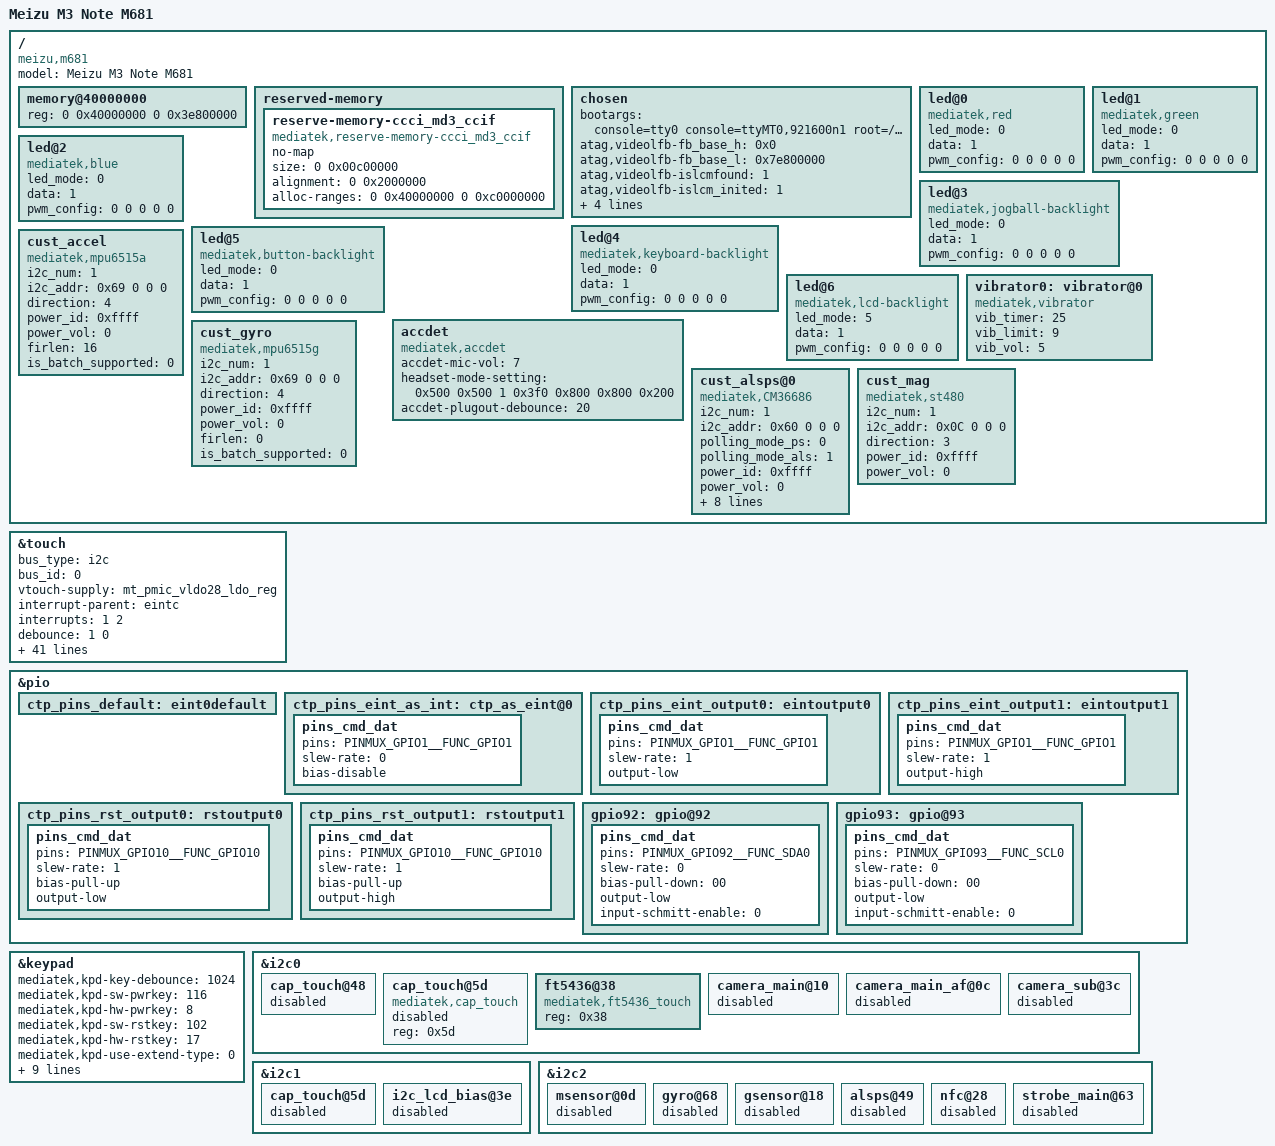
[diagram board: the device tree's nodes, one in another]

/*
 * !!! DEAD FILE — DO NOT EDIT FOR DEVICE CHANGES !!!  (m681 v240)
 * The boot.img packs ONLY wt6755_66_sz_l.dtb:
 *   m681_defconfig: CONFIG_BUILD_ARM64_APPENDED_DTB_IMAGE_NAMES="wt6755_66_sz_l"
 * Nothing in this file reaches the flashed kernel. All v239h11/h12 overrides
 * that were written here (keypad, led_mode, gpio92/93) were silently discarded
 * and had to be re-applied in wt6755_66_sz_l.dts. Put ALL board/DTS changes in
 * arch/arm64/boot/dts/wt6755_66_sz_l.dts instead. Kept only for git history.
 */
/dts-v1/;

#include "mt6755.dtsi"
#include "cust.dtsi"

/ {
	model = "Meizu M3 Note M681";
	compatible = "meizu,m681", "mediatek,mt6755";

	memory@40000000 {
		device_type = "memory";
		reg = <0 0x40000000 0 0x3e800000>;
	};

	reserved-memory {
		#address-cells = <2>;
		#size-cells = <2>;
		ranges;

		reserve-memory-ccci_md3_ccif {
			compatible = "mediatek,reserve-memory-ccci_md3_ccif";
			no-map;
			size = <0 0x00c00000>;
			alignment = <0 0x2000000>;
			alloc-ranges = <0 0x40000000 0 0xc0000000>;
		};
	};

	/* chosen */
	chosen {
		bootargs = "console=tty0 console=ttyMT0,921600n1 root=/dev/ram initrd=0x44000000,0x4b434e loglevel=4 printk.disable_uart=1 maxcpus=1 clk_ignore_unused";

		/* Real M681 boots through LK, so keep the fallback in sync with LK handoff. */
		/* fb buffer is reserved using this dts by memory node above */
		atag,videolfb-fb_base_h = <0x0>;
		atag,videolfb-fb_base_l = <0x7e800000>;
		atag,videolfb-islcmfound = <1>;
		atag,videolfb-islcm_inited = <1>;
		atag,videolfb-fps= <5716>;
		atag,videolfb-vramSize= <0x01be0000>;
		atag,videolfb-lcmname= "ili9885_fhd_dsi_vdo_txd1";
	};
	led@0 {
		compatible = "mediatek,red";
		led_mode = <0>;
		data = <1>;
		pwm_config = <0 0 0 0 0>;
	};
	led@1 {
		compatible = "mediatek,green";
		led_mode = <0>;
		data = <1>;
		pwm_config = <0 0 0 0 0>;
	};
	led@2 {
		compatible = "mediatek,blue";
		led_mode = <0>;
		data = <1>;
		pwm_config = <0 0 0 0 0>;
	};
	led@3 {
		compatible = "mediatek,jogball-backlight";
		led_mode = <0>;
		data = <1>;
		pwm_config = <0 0 0 0 0>;
	};
	led@4 {
		compatible = "mediatek,keyboard-backlight";
		led_mode = <0>;
		data = <1>;
		pwm_config = <0 0 0 0 0>;
	};
	led@5 {
		compatible = "mediatek,button-backlight";
		led_mode = <0>;
		data = <1>;
		pwm_config = <0 0 0 0 0>;
	};
	led@6 {
		compatible = "mediatek,lcd-backlight";
		/* m681 v239h12: was <7> (out of range — enum only 0..5). Stock m6
		 * uses <5> = MT65XX_LED_MODE_CUST_BLS_PWM, the only mode that
		 * hooks the backlight into the display blank/unblank path via the
		 * BLS/DISP_PWM block. led_mode=7 fell through to MODE_NONE, so the
		 * LED subsystem never controlled the BL and it stayed on at the
		 * LCM-init level forever (incl. when screen locked). */
		led_mode = <5>;
		data = <1>;
		pwm_config = <0 0 0 0 0>;
	};
	vibrator0:vibrator@0 {
		compatible = "mediatek,vibrator";
		vib_timer = <25>;
		vib_limit = <9>;
		vib_vol= <5>;
	};
	accdet {
		compatible = "mediatek,accdet";
		accdet-mic-vol = <7>;
		headset-mode-setting = <0x500 0x500 1 0x3f0 0x800 0x800 0x200>;
		accdet-plugout-debounce = <20>;
	};
/*  start sensor */
	/* m681 (wt6755_66_sz_l stock) sensors. alsps=CM36686, accel+gyro=MPU6515,
	 * mag=ST480, all on i2c bus 1. Chip + i2c_addr + direction taken from the
	 * stock m3note cust_acc.c/cust_gyro.c/cust_mag.c. compatible strings match
	 * the 3.18 driver get_*_dts_func() name lookups. */
	cust_accel {
		compatible = "mediatek,mpu6515a";
		i2c_num = <1>;
		i2c_addr = <0x69 0 0 0>;
		direction = <4>;
		power_id = <0xffff>;
		power_vol = <0>;
		firlen = <16>;
		is_batch_supported = <0>;
	};
	cust_gyro {
		compatible = "mediatek,mpu6515g";
		i2c_num = <1>;
		i2c_addr = <0x69 0 0 0>;
		direction = <4>;
		power_id = <0xffff>;
		power_vol = <0>;
		firlen = <0>;
		is_batch_supported = <0>;
	};
	cust_alsps@0 {
		compatible 				= "mediatek,CM36686";
		i2c_num 				= <1>;
		i2c_addr 				= <0x60 0 0 0>;
		polling_mode_ps			= <0>;
		polling_mode_als		= <1>;
		power_id   				= <0xffff>;
		power_vol  				= <0>;
		/* Total has 15 level*/
		als_level  				= <0 257 637 1027 2297 5588 6730 11301 20449 25768 31122 45552 57937 57937 57937>;
		/*  Total has 16 range*/
		als_value  				= <0 132 304 502 1004 2003 3006 5006 8004 10000 12000 16000 20000 20000 20000 20000>;
		ps_threshold_high		=  <70>;
		ps_threshold_low		=  <40>;
		is_batch_supported_ps	= <1>;
		is_batch_supported_als	= <1>;
	};
	cust_mag {
		compatible = "mediatek,st480";
		i2c_num = <1>;
		i2c_addr = <0x0C 0 0 0>;
		direction = <3>;
		power_id = <0xffff>;
		power_vol = <0>;
	};
/* end sensor */
};

/* TOUCH: ported verbatim from meizu_m6.dts — touch worked on m6, same MT6755
 * family/routing (INT=GPIO1, RST=GPIO42, vtouch=VLDO28, i2c0). m681 panel chip
 * confirmed via on-device i2c0 scan; ft5x26@0x38 enabled as the m6-proven default. */
&touch {
	bus_type = "i2c";
	bus_id = <0>;
	/* M6: stock Flyme DTB powers the touch panel from vldo28 (vtouch-supply =
	 * ldo_vldo28), NOT the SoC-default "vtouch" rail. mt6755.dtsi inherits
	 * vtouch-supply=<&mt_pmic_vtouch_ldo_reg>, but this PMIC has no VTOUCH LDO
	 * -> regulator_get(vtouch) returns -EPROBE_DEFER forever -> VLDO28 never
	 * enabled -> GT9xx chip unpowered -> i2c no-ACK at 0x5d (only bias 0x3e
	 * answers on i2c-0). Re-point the supply at the real rail so the framework
	 * enables it. FACT: live LDO_VLDO28_STATUS=0 before, stock vtouch-supply=
	 * ldo_vldo28; FORGE I2C0 SCAN showed only 0x3e ACK. */
	vtouch-supply = <&mt_pmic_vldo28_ldo_reg>;
	/* M6: ft5x26 takes its touch IRQ via irq_of_parse_and_map(touch_node,0).
	 * Stock Flyme touch node has interrupt-parent=<&eintc> interrupts=<1 2>
	 * (EINT line 1 = GPIO1 INT, type 2 = falling edge). GT9xx never reached
	 * IRQ setup (died at i2c-test) so this was latent; ft5x26 needs it. */
	interrupt-parent = <&eintc>;
	interrupts = <1 2>;
	debounce = <1 0>;
	charger_supported = <1>;
	product = "Jim";
	slave_address = <93 72 0 0 0 0 0 0 0 0 0 0 0 0 0 0>;
	algo_id = <1>;
	hmx_irq_config = <3>;
	goodix_irq_config = <2>;
	need_wd_check_status = <1>;
	x_max = <720>;
	y_max = <1280>;
	x_max_mt = <720>;
	y_max_mt = <1280>;
	goodix,product_id = "GT917D";
	goodix,test-types = <0x80007>;/*test types*/
	goodix,panel-max = <3948>;
	goodix,panel-min = <1897>;
	goodix,panel-deviation = <400>;
	goodix,key-max = <0>;
	goodix,key-min = <0>;
	goodix,key-nc = <0>;/*key test not check*/
	goodix,special_raw_data_limit = <>;
	goodix,shortcircut-threshold = <0>;
	fw_upgrade_delay = <30000>;
	/* stock Flyme DTB value (chip outputs 1080x1920-space coords) */
	tpd-resolution = <1080 1920>;
	use-tpd-button = <0>;
	tpd-key-num = <3>;
	tpd-key-local= <139 172 158 0>;
	tpd-key-dim-local = <90 883 100 40 230 883 100 40 370 883 100 40 0 0 0 0>;
	tpd-max-touch-num = <5>;
	tpd-filter-enable = <1>;
	tpd-filter-pixel-density = <146>;
	tpd-filter-custom-prameters = <0 0 0 0 0 0 0 0 0 0 0 0>;
	tpd-filter-custom-speed = <0 0 0>;
	pinctrl-names = "default", "state_eint_as_int", "state_eint_output0", "state_eint_output1",
		"state_rst_output0", "state_rst_output1";
	pinctrl-0 = <&ctp_pins_default>;
	pinctrl-1 = <&ctp_pins_eint_as_int>;
	pinctrl-2 = <&ctp_pins_eint_output0>;
	pinctrl-3 = <&ctp_pins_eint_output1>;
	pinctrl-4 = <&ctp_pins_rst_output0>;
	pinctrl-5 = <&ctp_pins_rst_output1>;
	status = "okay";
};
&pio {
	ctp_pins_default: eint0default {
	};
	ctp_pins_eint_as_int: ctp_as_eint@0 {
		pins_cmd_dat {
			pins = <PINMUX_GPIO1__FUNC_GPIO1>;
			slew-rate = <0>;
			bias-disable;
		};
	};
	ctp_pins_eint_output0: eintoutput0 {
		pins_cmd_dat {
			pins = <PINMUX_GPIO1__FUNC_GPIO1>;
			slew-rate = <1>;
			output-low;
		};
	};
	ctp_pins_eint_output1: eintoutput1 {
		pins_cmd_dat {
			pins = <PINMUX_GPIO1__FUNC_GPIO1>;
			slew-rate = <1>;
			output-high;
		};
	};
	ctp_pins_rst_output0: rstoutput0 {
		pins_cmd_dat {
			/* m681 stock (cust_gpio_usage.h): touch RST = GPIO10 */
			pins = <PINMUX_GPIO10__FUNC_GPIO10>;
			slew-rate = <1>;
			bias-pull-up;
			output-low;
		};
	};
	ctp_pins_rst_output1: rstoutput1 {
		pins_cmd_dat {
			pins = <PINMUX_GPIO10__FUNC_GPIO10>;
			slew-rate = <1>;
			bias-pull-up;
			output-high;
		};
	};
	/* m681 v239h12: i2c0 SCL/SDA pinmux. Stock cust_gpio.dtsi (wt6755_66_sz_l
	 * DCT) configures GPIO92=SDA0, GPIO93=SCL0. The graft DTS never included
	 * cust_gpio.dtsi, so the i2c0 controller ran (ACKERR) but the SCL/SDA
	 * pads stayed in GPIO mode -> full 7-bit scan found 0 ACKs and the touch
	 * chip never answered. These two nodes match the stock DCT pin config
	 * verbatim (slew/bias/schmitt are harmless in SDA0/SCL0 altfn — the i2c
	 * controller overrides the pad driver once mode=1). The touch driver also
	 * sets these via direct mt_set_gpio_mode() as a guaranteed fallback in
	 * case the graft pinctrl driver does not apply &pio sub-nodes (it did not
	 * for GPIO10 — see v239h10 handoff). */
	gpio92: gpio@92 {
		pins_cmd_dat {
			pins = <PINMUX_GPIO92__FUNC_SDA0>;
			slew-rate = <0>;
			bias-pull-down = <00>;
			output-low;
			input-schmitt-enable = <0>;
		};
	};
	gpio93: gpio@93 {
		pins_cmd_dat {
			pins = <PINMUX_GPIO93__FUNC_SCL0>;
			slew-rate = <0>;
			bias-pull-down = <00>;
			output-low;
			input-schmitt-enable = <0>;
		};
	};
};

/* m681 v239h12: keypad override — align with stock wt6755_66_sz_l DCT
 * (cust_kpd.dtsi). The graft cust.dtsi had kpd-hw-init-map=<114 0 ...>
 * (VOLDOWN only, VOLUP via rstkey) which deviates from stock. Stock DCT
 * maps VOLDOWN=114 at matrix pos0, VOLUMEUP=115 at matrix pos1, and the
 * rstkey (hw keycode 17) = KEY_HOME (102). Power key via PMIC (sw-pwrkey=116).
 * User reports VOL+/- and power all non-functional; this override restores
 * the stock matrix wiring. A [FORGE_KPD] probe marker in kpd.c confirms
 * whether the driver actually bound + loaded these values. */
&keypad {
	mediatek,kpd-key-debounce = <1024>;
	mediatek,kpd-sw-pwrkey = <116>;
	mediatek,kpd-hw-pwrkey = <8>;
	mediatek,kpd-sw-rstkey = <102>;
	mediatek,kpd-hw-rstkey = <17>;
	mediatek,kpd-use-extend-type = <0>;
	mediatek,kpd-hw-map-num = <72>;
	mediatek,kpd-hw-init-map = <114 115 0 0 0 0 0 0 0 0 0 0 0 0 0 0 0 0 0 0 0 0 0 0
				0 0 0 0 0 0 0 0 0 0 0 0 0 0 0 0 0 0 0 0 0 0 0 0
				0 0 0 0 0 0 0 0 0 0 0 0 0 0 0 0 0 0 0 0 0 0 0 0 >;
	mediatek,kpd-pwrkey-eint-gpio = <0>;
	mediatek,kpd-pwrkey-gpio-din = <0>;
	mediatek,kpd-hw-dl-key1 = <0>;
	mediatek,kpd-hw-dl-key2 = <8>;
	mediatek,kpd-hw-recovery-key = <1>;
	mediatek,kpd-hw-factory-key = <0>;
};

&i2c0 {
	/* donor (Honor "Jim") himax addr 0x48 from drvgen cust.dtsi — real M6 has no chip there */
	cap_touch@48 {
		status = "disabled";
	};
	/* stock Flyme 7.1.2.0G DTB claims Goodix GT9xx@0x5d, but THIS unit's panel
	 * is Focaltech FT5x46@0x38 (verified live: chip-id reg 0xA3=0x54="FT5x46",
	 * 0xA8 vendor=0x80). Goodix driver no-ACKs at 0x5d forever. Disable the
	 * Goodix node, bind the FT5x26 driver at 0x38 instead. */
	cap_touch@5d {
		compatible = "mediatek,cap_touch";
		reg = <0x5d>;
		status = "disabled";
	};
	ft5436@38 {
		compatible = "mediatek,ft5436_touch";
		reg = <0x38>;
		/* m681 v239h9: switched from ft5x26 to stock ft5436 driver */
		status = "okay";
	};
};

/* m681 v239: re-enable i2c clients. The v221 mass-disable was a workaround for
 * a boot hang caused by the disp_input_config struct mismatch (fixed in v238b).
 * Enable touch (i2c0), lcd_bias (i2c1), and sensors (i2c2) one step at a time. */
&i2c0 {
	camera_main@10 { status = "disabled"; };
	camera_main_af@0c { status = "disabled"; };
	camera_sub@3c { status = "disabled"; };
};
&i2c1 {
	cap_touch@5d { status = "disabled"; };
	i2c_lcd_bias@3e { status = "disabled"; };
};
&i2c2 {
	msensor@0d { status = "disabled"; };
	gyro@68 { status = "disabled"; };
	gsensor@18 { status = "disabled"; };
	alsps@49 { status = "disabled"; };
	nfc@28 { status = "disabled"; };
	strobe_main@63 { status = "disabled"; };
};
